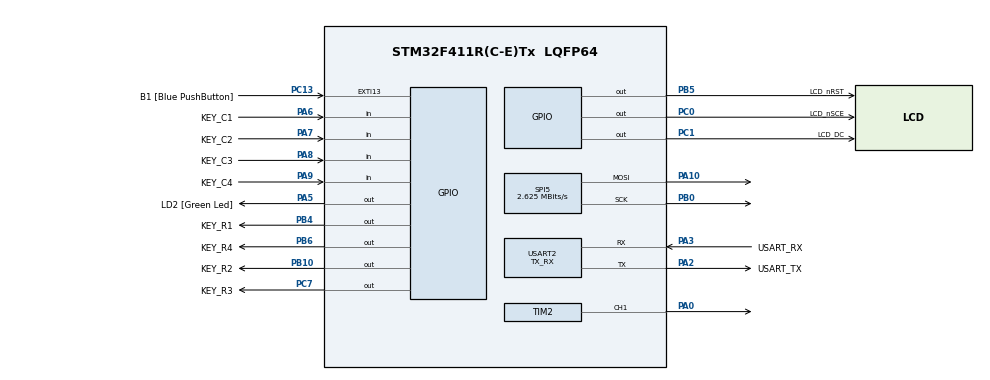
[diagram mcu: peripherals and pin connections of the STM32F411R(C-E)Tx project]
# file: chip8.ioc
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Mcu.Family=STM32F4
Mcu.Name=STM32F411R(C-E)Tx
Mcu.Package=LQFP64
NVIC.EXTI15_10_IRQn=true\:0\:0\:false\:false\:true\:true\:true\:true
NVIC.PriorityGroup=NVIC_PRIORITYGROUP_0
PA0-WKUP.Signal=S_TIM2_CH1_ETR
PA10.Mode=TX_Only_Simplex_Unidirect_Master
PA10.Signal=SPI5_MOSI
PA13.GPIO_Label=TMS
PA13.Mode=Serial_Wire
PA13.Signal=SYS_JTMS-SWDIO
PA14.GPIO_Label=TCK
PA14.Mode=Serial_Wire
PA14.Signal=SYS_JTCK-SWCLK
PA2.GPIO_Label=USART_TX
PA2.Mode=Asynchronous
PA2.Signal=USART2_TX
PA3.GPIO_Label=USART_RX
PA3.Mode=Asynchronous
PA3.Signal=USART2_RX
PA5.GPIO_Label=LD2 [Green Led]
PA5.Signal=GPIO_Output
PA6.GPIO_Label=KEY_C1
PA6.GPIO_PuPd=GPIO_PULLDOWN
PA6.Signal=GPIO_Input
PA7.GPIO_Label=KEY_C2
PA7.GPIO_PuPd=GPIO_PULLDOWN
PA7.Signal=GPIO_Input
PA8.GPIO_Label=KEY_C3
PA8.GPIO_PuPd=GPIO_PULLDOWN
PA8.Signal=GPIO_Input
PA9.GPIO_Label=KEY_C4
PA9.GPIO_PuPd=GPIO_PULLDOWN
PA9.Signal=GPIO_Input
PB0.Mode=TX_Only_Simplex_Unidirect_Master
PB0.Signal=SPI5_SCK
PB10.GPIO_Label=KEY_R2
PB10.Signal=GPIO_Output
PB3.GPIO_Label=SWO
PB3.Signal=SYS_JTDO-SWO
PB4.GPIO_Label=KEY_R1
PB4.Signal=GPIO_Output
PB5.GPIO_Label=LCD_nRST
PB5.PinState=GPIO_PIN_SET
PB5.Signal=GPIO_Output
PB6.GPIO_Label=KEY_R4
PB6.Signal=GPIO_Output
PC0.GPIO_Label=LCD_nSCE
PC0.PinState=GPIO_PIN_SET
PC0.Signal=GPIO_Output
PC1.GPIO_Label=LCD_DC
PC1.Signal=GPIO_Output
PC13-ANTI_TAMP.GPIO_Label=B1 [Blue PushButton]
PC13-ANTI_TAMP.GPIO_ModeDefaultEXTI=GPIO_MODE_IT_FALLING
PC13-ANTI_TAMP.Signal=GPXTI13
PC14-OSC32_IN.Mode=LSE-External-Oscillator
PC14-OSC32_IN.Signal=RCC_OSC32_IN
PC15-OSC32_OUT.Mode=LSE-External-Oscillator
PC15-OSC32_OUT.Signal=RCC_OSC32_OUT
PC7.GPIO_Label=KEY_R3
PC7.Signal=GPIO_Output
PH0\ -\ OSC_IN.Mode=HSE-External-Clock-Source
PH0\ -\ OSC_IN.Signal=RCC_OSC_IN
PH1\ -\ OSC_OUT.Mode=HSE-External-Clock-Source
PH1\ -\ OSC_OUT.Signal=RCC_OSC_OUT
ProjectManager.HeapSize=0x2000
ProjectManager.StackSize=0x400
ProjectManager.TargetToolchain=STM32CubeIDE
RCC.48MHZClocksFreq_Value=84000000
RCC.AHBFreq_Value=84000000
RCC.APB1CLKDivider=RCC_HCLK_DIV2
RCC.APB1Freq_Value=42000000
RCC.APB1TimFreq_Value=84000000
RCC.APB2Freq_Value=84000000
RCC.APB2TimFreq_Value=84000000
RCC.CortexFreq_Value=84000000
RCC.FLatency-AdvancedSettings=FLASH_LATENCY_2
RCC.HCLKFreq_Value=84000000
RCC.HSE_VALUE=8000000
RCC.HSI_VALUE=16000000
RCC.PLLN=336
RCC.PLLP=RCC_PLLP_DIV4
RCC.SYSCLKFreq_VALUE=84000000
RCC.SYSCLKSource=RCC_SYSCLKSOURCE_PLLCLK
RCC.VCOOutputFreq_Value=336000000
SH.S_TIM2_CH1_ETR.0=TIM2_CH1,PWM Generation1 CH1
SPI5.BaudRatePrescaler=SPI_BAUDRATEPRESCALER_32
SPI5.CLKPhase=SPI_PHASE_2EDGE
SPI5.CLKPolarity=SPI_POLARITY_HIGH
SPI5.CalculateBaudRate=2.625 MBits/s
SPI5.Direction=SPI_DIRECTION_2LINES
SPI5.Mode=SPI_MODE_MASTER
SPI5.VirtualType=VM_MASTER
TIM2.Channel-PWM\ Generation1\ CH1=TIM_CHANNEL_1
TIM2.Period=20999
TIM2.Pulse-PWM\ Generation1\ CH1=10500
TIM3.ClockDivision=TIM_CLOCKDIVISION_DIV1
TIM3.Period=41999
TIM3.Prescaler=3
TIM4.ClockDivision=TIM_CLOCKDIVISION_DIV1
TIM4.Period=43749
TIM4.Prescaler=31
USART2.Mode=MODE_TX_RX
USART2.VirtualMode=VM_ASYNC
VP_TIM2_VS_ClockSourceINT.Mode=Internal
VP_TIM3_VS_ClockSourceINT.Mode=Internal
VP_TIM4_VS_ClockSourceINT.Mode=Internal
board=NUCLEO-F411RE

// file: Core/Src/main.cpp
/* USER CODE BEGIN Header */
/**
 ******************************************************************************
 * @file           : main.c
 * @brief          : Main program body
 ******************************************************************************
 * @attention
 *
 * Copyright (c) 2022 STMicroelectronics.
 * All rights reserved.
 *
 * This software is licensed under terms that can be found in the LICENSE file
 * in the root directory of this software component.
 * If no LICENSE file comes with this software, it is provided AS-IS.
 *
 ******************************************************************************
 */
/* USER CODE END Header */
#include "main.h"

/* USER CODE BEGIN Includes */
#include "chip8.hpp"

#include <memory>
/* USER CODE END Includes */

void SystemClock_Config(void);
static void MX_GPIO_Init(void);
static void MX_USART2_UART_Init(void);
static void MX_SPI5_Init(void);
static void MX_TIM3_Init(void);
static void MX_TIM4_Init(void);
static void MX_TIM2_Init(void);

int main(void)
{

    /* MCU
     * Configuration--------------------------------------------------------*/

    /* Reset of all peripherals, Initializes the Flash interface and the
     * Systick. */
    LL_APB2_GRP1_EnableClock(LL_APB2_GRP1_PERIPH_SYSCFG);
    LL_APB1_GRP1_EnableClock(LL_APB1_GRP1_PERIPH_PWR);

    /* System interrupt init*/
    NVIC_SetPriorityGrouping(NVIC_PRIORITYGROUP_0);

    /* Configure the system clock */
    SystemClock_Config();

    /* Initialize all configured peripherals */
    MX_GPIO_Init();
    MX_USART2_UART_Init();
    MX_SPI5_Init();
    MX_TIM3_Init();
    MX_TIM4_Init();
    MX_TIM2_Init();
    /* USER CODE BEGIN 2 */
    auto chip8app = std::make_unique<CHIP8>();
    // static CHIP8 chip8app;
    /* USER CODE END 2 */

    /* Infinite loop */
    /* USER CODE BEGIN WHILE */
    while(true)
    {
        /* USER CODE END WHILE */

        /* USER CODE BEGIN 3 */
        chip8app->run();
        // chip8app.run();
    }
    /* USER CODE END 3 */
}

void SystemClock_Config(void)
{
    LL_FLASH_SetLatency(LL_FLASH_LATENCY_2);
    while(LL_FLASH_GetLatency() != LL_FLASH_LATENCY_2)
    {
    }
    LL_PWR_SetRegulVoltageScaling(LL_PWR_REGU_VOLTAGE_SCALE1);
    LL_RCC_HSI_SetCalibTrimming(16);
    LL_RCC_HSI_Enable();

    /* Wait till HSI is ready */
    while(LL_RCC_HSI_IsReady() != 1)
    {
    }
    LL_RCC_PLL_ConfigDomain_SYS(LL_RCC_PLLSOURCE_HSI, LL_RCC_PLLM_DIV_16, 336,
        LL_RCC_PLLP_DIV_4);
    LL_RCC_PLL_Enable();

    /* Wait till PLL is ready */
    while(LL_RCC_PLL_IsReady() != 1)
    {
    }
    LL_RCC_SetAHBPrescaler(LL_RCC_SYSCLK_DIV_1);
    LL_RCC_SetAPB1Prescaler(LL_RCC_APB1_DIV_2);
    LL_RCC_SetAPB2Prescaler(LL_RCC_APB2_DIV_1);
    LL_RCC_SetSysClkSource(LL_RCC_SYS_CLKSOURCE_PLL);

    /* Wait till System clock is ready */
    while(LL_RCC_GetSysClkSource() != LL_RCC_SYS_CLKSOURCE_STATUS_PLL)
    {
    }
    LL_Init1msTick(84000000);
    LL_SetSystemCoreClock(84000000);
    LL_RCC_SetTIMPrescaler(LL_RCC_TIM_PRESCALER_TWICE);
}

static void MX_SPI5_Init(void)
{

    LL_SPI_InitTypeDef SPI_InitStruct = {0};

    LL_GPIO_InitTypeDef GPIO_InitStruct = {0};

    /* Peripheral clock enable */
    LL_APB2_GRP1_EnableClock(LL_APB2_GRP1_PERIPH_SPI5);

    LL_AHB1_GRP1_EnableClock(LL_AHB1_GRP1_PERIPH_GPIOB);
    LL_AHB1_GRP1_EnableClock(LL_AHB1_GRP1_PERIPH_GPIOA);
    /**SPI5 GPIO Configuration
    PB0   ------> SPI5_SCK
    PA10   ------> SPI5_MOSI
    */
    GPIO_InitStruct.Pin        = LL_GPIO_PIN_0;
    GPIO_InitStruct.Mode       = LL_GPIO_MODE_ALTERNATE;
    GPIO_InitStruct.Speed      = LL_GPIO_SPEED_FREQ_VERY_HIGH;
    GPIO_InitStruct.OutputType = LL_GPIO_OUTPUT_PUSHPULL;
    GPIO_InitStruct.Pull       = LL_GPIO_PULL_NO;
    GPIO_InitStruct.Alternate  = LL_GPIO_AF_6;
    LL_GPIO_Init(GPIOB, &GPIO_InitStruct);

    GPIO_InitStruct.Pin        = LL_GPIO_PIN_10;
    GPIO_InitStruct.Mode       = LL_GPIO_MODE_ALTERNATE;
    GPIO_InitStruct.Speed      = LL_GPIO_SPEED_FREQ_VERY_HIGH;
    GPIO_InitStruct.OutputType = LL_GPIO_OUTPUT_PUSHPULL;
    GPIO_InitStruct.Pull       = LL_GPIO_PULL_NO;
    GPIO_InitStruct.Alternate  = LL_GPIO_AF_6;
    LL_GPIO_Init(GPIOA, &GPIO_InitStruct);

    /* SPI5 parameter configuration*/
    SPI_InitStruct.TransferDirection = LL_SPI_FULL_DUPLEX;
    SPI_InitStruct.Mode              = LL_SPI_MODE_MASTER;
    SPI_InitStruct.DataWidth         = LL_SPI_DATAWIDTH_8BIT;
    SPI_InitStruct.ClockPolarity     = LL_SPI_POLARITY_HIGH;
    SPI_InitStruct.ClockPhase        = LL_SPI_PHASE_2EDGE;
    SPI_InitStruct.NSS               = LL_SPI_NSS_SOFT;
    SPI_InitStruct.BaudRate          = LL_SPI_BAUDRATEPRESCALER_DIV32;
    SPI_InitStruct.BitOrder          = LL_SPI_MSB_FIRST;
    SPI_InitStruct.CRCCalculation    = LL_SPI_CRCCALCULATION_DISABLE;
    SPI_InitStruct.CRCPoly           = 10;
    LL_SPI_Init(SPI5, &SPI_InitStruct);
    LL_SPI_SetStandard(SPI5, LL_SPI_PROTOCOL_MOTOROLA);
}

static void MX_TIM2_Init(void)
{

    LL_TIM_InitTypeDef TIM_InitStruct       = {0};
    LL_TIM_OC_InitTypeDef TIM_OC_InitStruct = {0};

    LL_GPIO_InitTypeDef GPIO_InitStruct = {0};

    /* Peripheral clock enable */
    LL_APB1_GRP1_EnableClock(LL_APB1_GRP1_PERIPH_TIM2);

    TIM_InitStruct.Prescaler     = 0;
    TIM_InitStruct.CounterMode   = LL_TIM_COUNTERMODE_UP;
    TIM_InitStruct.Autoreload    = 20999;
    TIM_InitStruct.ClockDivision = LL_TIM_CLOCKDIVISION_DIV1;
    LL_TIM_Init(TIM2, &TIM_InitStruct);
    LL_TIM_DisableARRPreload(TIM2);
    LL_TIM_SetClockSource(TIM2, LL_TIM_CLOCKSOURCE_INTERNAL);
    LL_TIM_OC_EnablePreload(TIM2, LL_TIM_CHANNEL_CH1);
    TIM_OC_InitStruct.OCMode       = LL_TIM_OCMODE_PWM1;
    TIM_OC_InitStruct.OCState      = LL_TIM_OCSTATE_DISABLE;
    TIM_OC_InitStruct.OCNState     = LL_TIM_OCSTATE_DISABLE;
    TIM_OC_InitStruct.CompareValue = 10500;
    TIM_OC_InitStruct.OCPolarity   = LL_TIM_OCPOLARITY_HIGH;
    LL_TIM_OC_Init(TIM2, LL_TIM_CHANNEL_CH1, &TIM_OC_InitStruct);
    LL_TIM_OC_DisableFast(TIM2, LL_TIM_CHANNEL_CH1);
    LL_TIM_SetTriggerOutput(TIM2, LL_TIM_TRGO_RESET);
    LL_TIM_DisableMasterSlaveMode(TIM2);
    LL_AHB1_GRP1_EnableClock(LL_AHB1_GRP1_PERIPH_GPIOA);
    /**TIM2 GPIO Configuration
    PA0-WKUP   ------> TIM2_CH1
    */
    GPIO_InitStruct.Pin        = LL_GPIO_PIN_0;
    GPIO_InitStruct.Mode       = LL_GPIO_MODE_ALTERNATE;
    GPIO_InitStruct.Speed      = LL_GPIO_SPEED_FREQ_LOW;
    GPIO_InitStruct.OutputType = LL_GPIO_OUTPUT_PUSHPULL;
    GPIO_InitStruct.Pull       = LL_GPIO_PULL_NO;
    GPIO_InitStruct.Alternate  = LL_GPIO_AF_1;
    LL_GPIO_Init(GPIOA, &GPIO_InitStruct);
}

static void MX_TIM3_Init(void)
{

    LL_TIM_InitTypeDef TIM_InitStruct = {0};

    /* Peripheral clock enable */
    LL_APB1_GRP1_EnableClock(LL_APB1_GRP1_PERIPH_TIM3);

    TIM_InitStruct.Prescaler     = 3;
    TIM_InitStruct.CounterMode   = LL_TIM_COUNTERMODE_UP;
    TIM_InitStruct.Autoreload    = 41999;
    TIM_InitStruct.ClockDivision = LL_TIM_CLOCKDIVISION_DIV1;
    LL_TIM_Init(TIM3, &TIM_InitStruct);
    LL_TIM_DisableARRPreload(TIM3);
    LL_TIM_SetClockSource(TIM3, LL_TIM_CLOCKSOURCE_INTERNAL);
    LL_TIM_SetTriggerOutput(TIM3, LL_TIM_TRGO_RESET);
    LL_TIM_DisableMasterSlaveMode(TIM3);
    /* USER CODE BEGIN TIM3_Init 2 */
    LL_TIM_ClearFlag_UPDATE(TIM3);
    /* USER CODE END TIM3_Init 2 */
}

static void MX_TIM4_Init(void)
{

    LL_TIM_InitTypeDef TIM_InitStruct = {0};

    /* Peripheral clock enable */
    LL_APB1_GRP1_EnableClock(LL_APB1_GRP1_PERIPH_TIM4);

    TIM_InitStruct.Prescaler     = 31;
    TIM_InitStruct.CounterMode   = LL_TIM_COUNTERMODE_UP;
    TIM_InitStruct.Autoreload    = 43749;
    TIM_InitStruct.ClockDivision = LL_TIM_CLOCKDIVISION_DIV1;
    LL_TIM_Init(TIM4, &TIM_InitStruct);
    LL_TIM_DisableARRPreload(TIM4);
    LL_TIM_SetClockSource(TIM4, LL_TIM_CLOCKSOURCE_INTERNAL);
    LL_TIM_SetTriggerOutput(TIM4, LL_TIM_TRGO_RESET);
    LL_TIM_DisableMasterSlaveMode(TIM4);
    /* USER CODE BEGIN TIM4_Init 2 */
    LL_TIM_ClearFlag_UPDATE(TIM4);
    /* USER CODE END TIM4_Init 2 */
}

static void MX_USART2_UART_Init(void)
{

    LL_USART_InitTypeDef USART_InitStruct = {0};

    LL_GPIO_InitTypeDef GPIO_InitStruct = {0};

    /* Peripheral clock enable */
    LL_APB1_GRP1_EnableClock(LL_APB1_GRP1_PERIPH_USART2);

    LL_AHB1_GRP1_EnableClock(LL_AHB1_GRP1_PERIPH_GPIOA);
    /**USART2 GPIO Configuration
    PA2   ------> USART2_TX
    PA3   ------> USART2_RX
    */
    GPIO_InitStruct.Pin        = USART_TX_Pin | USART_RX_Pin;
    GPIO_InitStruct.Mode       = LL_GPIO_MODE_ALTERNATE;
    GPIO_InitStruct.Speed      = LL_GPIO_SPEED_FREQ_VERY_HIGH;
    GPIO_InitStruct.OutputType = LL_GPIO_OUTPUT_PUSHPULL;
    GPIO_InitStruct.Pull       = LL_GPIO_PULL_NO;
    GPIO_InitStruct.Alternate  = LL_GPIO_AF_7;
    LL_GPIO_Init(GPIOA, &GPIO_InitStruct);

    USART_InitStruct.BaudRate            = 115200;
    USART_InitStruct.DataWidth           = LL_USART_DATAWIDTH_8B;
    USART_InitStruct.StopBits            = LL_USART_STOPBITS_1;
    USART_InitStruct.Parity              = LL_USART_PARITY_NONE;
    USART_InitStruct.TransferDirection   = LL_USART_DIRECTION_TX_RX;
    USART_InitStruct.HardwareFlowControl = LL_USART_HWCONTROL_NONE;
    USART_InitStruct.OverSampling        = LL_USART_OVERSAMPLING_16;
    LL_USART_Init(USART2, &USART_InitStruct);
    LL_USART_ConfigAsyncMode(USART2);
    LL_USART_Enable(USART2);
}

static void MX_GPIO_Init(void)
{
    LL_EXTI_InitTypeDef EXTI_InitStruct = {0};
    LL_GPIO_InitTypeDef GPIO_InitStruct = {0};

    /* GPIO Ports Clock Enable */
    LL_AHB1_GRP1_EnableClock(LL_AHB1_GRP1_PERIPH_GPIOC);
    LL_AHB1_GRP1_EnableClock(LL_AHB1_GRP1_PERIPH_GPIOH);
    LL_AHB1_GRP1_EnableClock(LL_AHB1_GRP1_PERIPH_GPIOA);
    LL_AHB1_GRP1_EnableClock(LL_AHB1_GRP1_PERIPH_GPIOB);

    /**/
    LL_GPIO_SetOutputPin(LCD_nSCE_GPIO_Port, LCD_nSCE_Pin);

    /**/
    LL_GPIO_SetOutputPin(LCD_nRST_GPIO_Port, LCD_nRST_Pin);

    /**/
    LL_GPIO_ResetOutputPin(GPIOC, LCD_DC_Pin | KEY_R3_Pin);

    /**/
    LL_GPIO_ResetOutputPin(LD2_GPIO_Port, LD2_Pin);

    /**/
    LL_GPIO_ResetOutputPin(GPIOB, KEY_R2_Pin | KEY_R1_Pin | KEY_R4_Pin);

    /**/
    LL_SYSCFG_SetEXTISource(LL_SYSCFG_EXTI_PORTC, LL_SYSCFG_EXTI_LINE13);

    /**/
    EXTI_InitStruct.Line_0_31   = LL_EXTI_LINE_13;
    EXTI_InitStruct.LineCommand = ENABLE;
    EXTI_InitStruct.Mode        = LL_EXTI_MODE_IT;
    EXTI_InitStruct.Trigger     = LL_EXTI_TRIGGER_FALLING;
    LL_EXTI_Init(&EXTI_InitStruct);

    /**/
    LL_GPIO_SetPinPull(B1_GPIO_Port, B1_Pin, LL_GPIO_PULL_NO);

    /**/
    LL_GPIO_SetPinMode(B1_GPIO_Port, B1_Pin, LL_GPIO_MODE_INPUT);

    /**/
    GPIO_InitStruct.Pin        = LCD_nSCE_Pin | LCD_DC_Pin | KEY_R3_Pin;
    GPIO_InitStruct.Mode       = LL_GPIO_MODE_OUTPUT;
    GPIO_InitStruct.Speed      = LL_GPIO_SPEED_FREQ_LOW;
    GPIO_InitStruct.OutputType = LL_GPIO_OUTPUT_PUSHPULL;
    GPIO_InitStruct.Pull       = LL_GPIO_PULL_NO;
    LL_GPIO_Init(GPIOC, &GPIO_InitStruct);

    /**/
    GPIO_InitStruct.Pin        = LD2_Pin;
    GPIO_InitStruct.Mode       = LL_GPIO_MODE_OUTPUT;
    GPIO_InitStruct.Speed      = LL_GPIO_SPEED_FREQ_LOW;
    GPIO_InitStruct.OutputType = LL_GPIO_OUTPUT_PUSHPULL;
    GPIO_InitStruct.Pull       = LL_GPIO_PULL_NO;
    LL_GPIO_Init(LD2_GPIO_Port, &GPIO_InitStruct);

    /**/
    GPIO_InitStruct.Pin  = KEY_C1_Pin | KEY_C2_Pin | KEY_C3_Pin | KEY_C4_Pin;
    GPIO_InitStruct.Mode = LL_GPIO_MODE_INPUT;
    GPIO_InitStruct.Pull = LL_GPIO_PULL_DOWN;
    LL_GPIO_Init(GPIOA, &GPIO_InitStruct);

    /**/
    GPIO_InitStruct.Pin   = KEY_R2_Pin | KEY_R1_Pin | LCD_nRST_Pin | KEY_R4_Pin;
    GPIO_InitStruct.Mode  = LL_GPIO_MODE_OUTPUT;
    GPIO_InitStruct.Speed = LL_GPIO_SPEED_FREQ_LOW;
    GPIO_InitStruct.OutputType = LL_GPIO_OUTPUT_PUSHPULL;
    GPIO_InitStruct.Pull       = LL_GPIO_PULL_NO;
    LL_GPIO_Init(GPIOB, &GPIO_InitStruct);

    /* EXTI interrupt init*/
    NVIC_SetPriority(EXTI15_10_IRQn,
        NVIC_EncodePriority(NVIC_GetPriorityGrouping(), 0, 0));
    NVIC_EnableIRQ(EXTI15_10_IRQn);
}

void Error_Handler(void)
{
    /* USER CODE BEGIN Error_Handler_Debug */
    /* User can add his own implementation to report the HAL error return state
     */
    __disable_irq();
    while(1)
    {
    }
    /* USER CODE END Error_Handler_Debug */
}

#ifdef USE_FULL_ASSERT
/**
 * @brief  Reports the name of the source file and the source line number
 *         where the assert_param error has occurred.
 * @param  file: pointer to the source file name
 * @param  line: assert_param error line source number
 * @retval None
 */
void assert_failed(uint8_t* file, uint32_t line)
{
    /* USER CODE BEGIN 6 */
    /* User can add his own implementation to report the file name and line
       number, ex: printf("Wrong parameters value: file %s on line %d\r\n",
       file, line) */
    /* USER CODE END 6 */
}
#endif /* USE_FULL_ASSERT */
